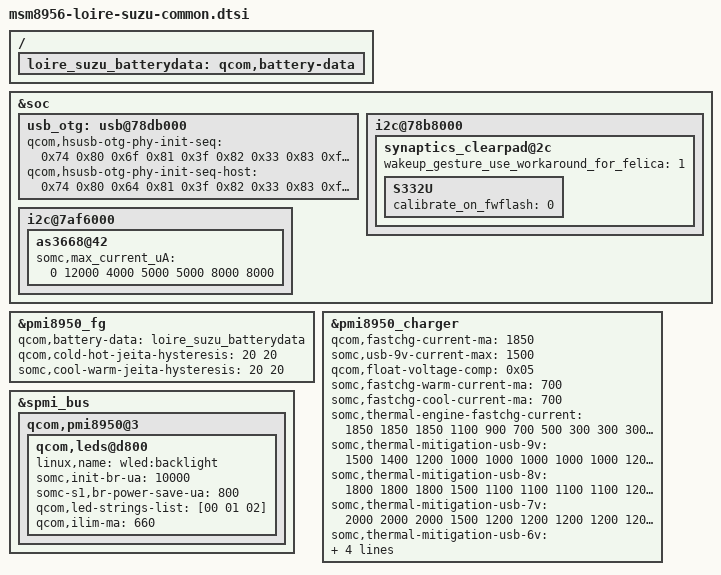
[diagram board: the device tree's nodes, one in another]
/* arch/arm/boot/dts/qcom/msm8956-loire-suzu-common.dtsi
 *
 * This program is free software; you can redistribute it and/or modify
 * it under the terms of the GNU General Public License version 2 and
 * only version 2 as published by the Free Software Foundation.
 *
 * This program is distributed in the hope that it will be useful,
 * but WITHOUT ANY WARRANTY; without even the implied warranty of
 * MERCHANTABILITY or FITNESS FOR A PARTICULAR PURPOSE.  See the
 * GNU General Public License for more details.
 */
/*
 * Copyright (C) 2015 Sony Mobile Communications Inc.
 *
 * This program is free software; you can redistribute it and/or modify
 * it under the terms of the GNU General Public License version 2, as
 * published by the Free Software Foundation.
 */

&soc {
	usb_otg: usb@78db000 {
		qcom,hsusb-otg-phy-init-seq =
			<0x74 0x80 0x6f 0x81 0x3f 0x82 0x33 0x83 0xffffffff>;
		qcom,hsusb-otg-phy-init-seq-host =
			<0x74 0x80 0x64 0x81 0x3f 0x82 0x33 0x83 0xffffffff>;
	};

	/* I2C : BLSP4 */
	i2c@78b8000 { /* BLSP1 QUP3 */
		synaptics_clearpad@2c {
			wakeup_gesture_use_workaround_for_felica = <1>;
			/* chip settings */
			S332U {
				calibrate_on_fwflash = <0>;
			};
		};
	};
	/* I2C : BLSP6 */
	i2c@7af6000 { /* BLSP2 QUP1 */
		as3668@42 {
			somc,max_current_uA = <0 12000 4000 5000 5000 8000 8000>;
		};
	};
};

/{
	loire_suzu_batterydata: qcom,battery-data {
		#include "batterydata-loire-suzu-send.dtsi"
		#include "batterydata-loire-suzu-atl.dtsi"
	};
};

&pmi8950_fg {
	qcom,battery-data = <&loire_suzu_batterydata>;
	qcom,cold-hot-jeita-hysteresis = <20 20>;
	somc,cool-warm-jeita-hysteresis = <20 20>;
};

&pmi8950_charger {
	qcom,fastchg-current-ma = <1850>;
	somc,usb-9v-current-max = <1500>;
	qcom,float-voltage-comp = <0x05>;
	somc,fastchg-warm-current-ma = <700>;
	somc,fastchg-cool-current-ma = <700>;
	somc,thermal-engine-fastchg-current = <1850 1850 1850 1100 900 700 500 300 300 300 300 300 300 0 0>;
	somc,thermal-mitigation-usb-9v = <1500 1400 1200 1000 1000 1000 1000 1000 1200 900 700 500 300 0 0>;
	somc,thermal-mitigation-usb-8v = <1800 1800 1800 1500 1100 1100 1100 1100 1200 900 700 500 300 0 0>;
	somc,thermal-mitigation-usb-7v = <2000 2000 2000 1500 1200 1200 1200 1200 1200 900 700 500 300 0 0>;
	somc,thermal-mitigation-usb-6v = <2000 2000 2000 1500 1500 1500 1500 1500 1200 900 700 500 300 0 0>;
	somc,thermal-mitigation-usb-5v = <1500 1500 1500 1500 1500 1500 1500 1500 1200 900 700 500 300 0 0>;
	somc,limit-usb-5v-level = <8>;
};

&spmi_bus {
	qcom,pmi8950@3 {
		qcom,leds@d800 {
			linux,name = "wled:backlight";
			somc,init-br-ua = <10000>;
			somc-s1,br-power-save-ua = <800>;
			qcom,led-strings-list = [00 01 02];
			qcom,ilim-ma = <660>;
		};
	};
};
